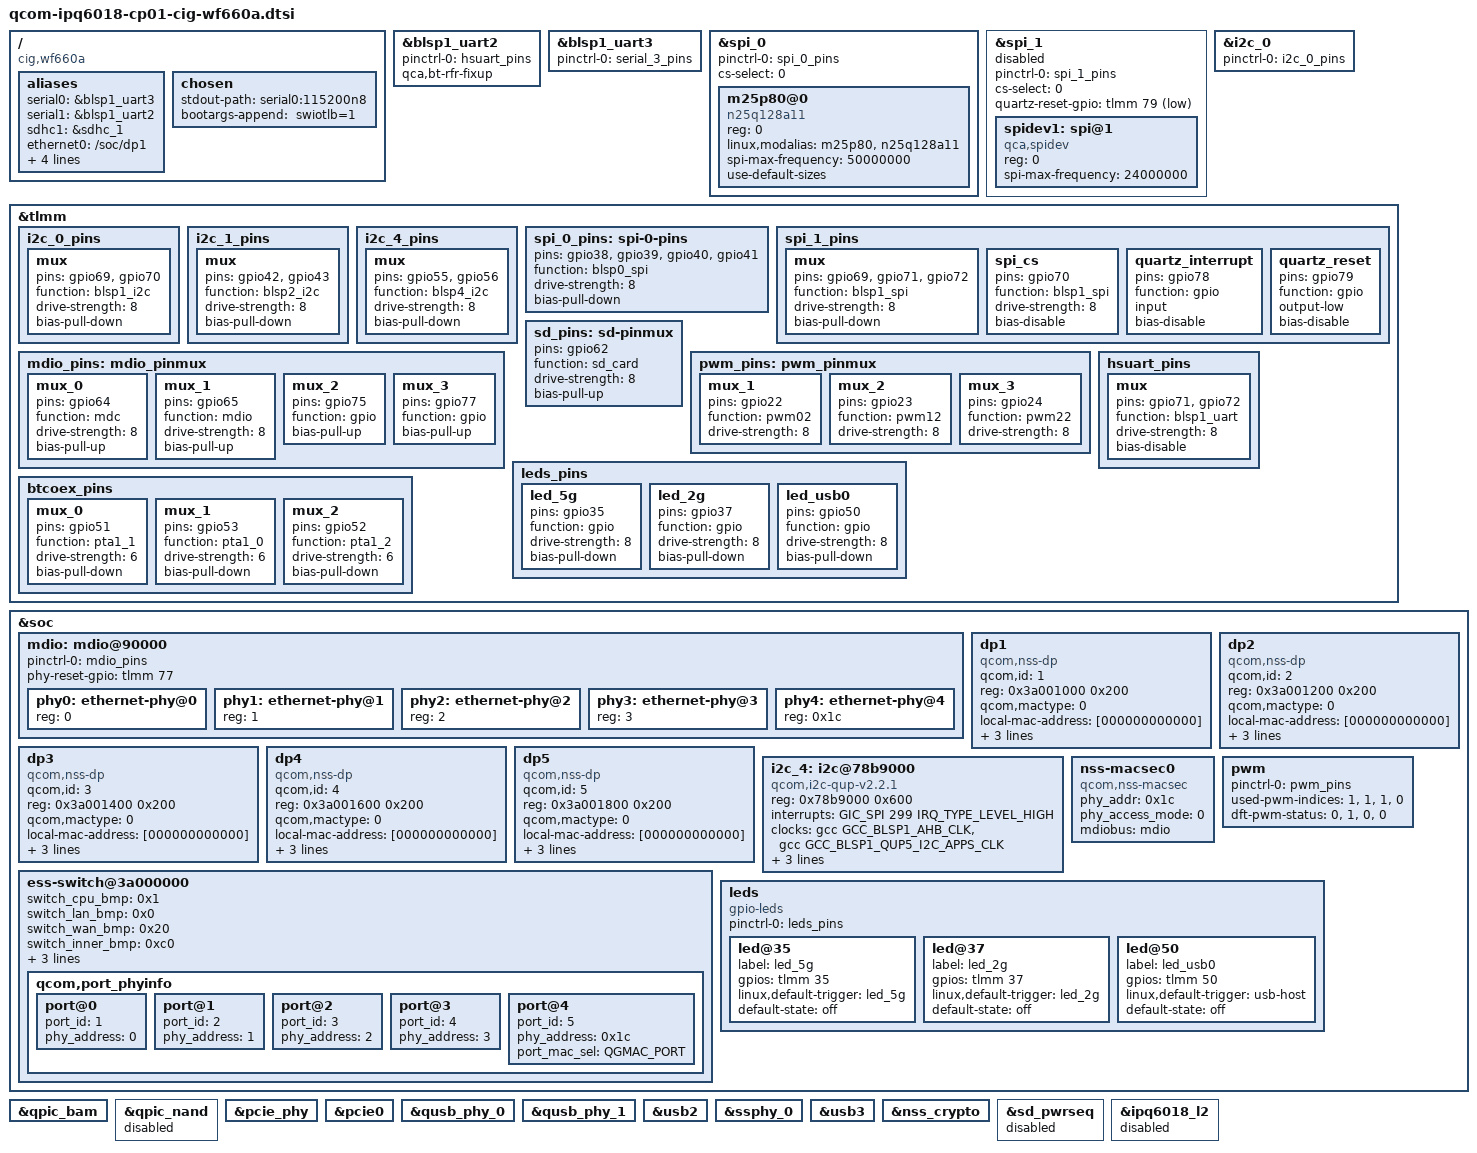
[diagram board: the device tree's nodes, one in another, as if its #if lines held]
// SPDX-License-Identifier: (GPL-2.0+ OR BSD-3-Clause)
/*
 * IPQ6018 CP01 board device tree source
 *
 * Copyright (c) 2019-2021 The Linux Foundation. All rights reserved.
 */

/dts-v1/;

#include "ipq6018.dtsi"
#include "ipq6018-cpr-regulator.dtsi"
#include <dt-bindings/input/input.h>
#include <dt-bindings/gpio/gpio.h>
#include <dt-bindings/pwm/pwm.h>

/ {
    compatible = "cig,wf660a", "qcom,ipq6018-ap-cp01", "qcom,ipq6018";

	aliases {
		serial0 = &blsp1_uart3;
		serial1 = &blsp1_uart2;
		sdhc1 = &sdhc_1;
		/*
		 * Aliases as required by u-boot
		 * to patch MAC addresses
		 */
		ethernet0 = "/soc/dp1";
		ethernet1 = "/soc/dp2";
		ethernet2 = "/soc/dp3";
		ethernet3 = "/soc/dp4";
		ethernet4 = "/soc/dp5";
	};

	chosen {
		stdout-path = "serial0:115200n8";
		bootargs-append = " swiotlb=1";
	};
};

&blsp1_uart2 {
	pinctrl-0 = <&hsuart_pins>;
	pinctrl-names = "default";
	qca,bt-rfr-fixup;
	status = "ok";
};

&blsp1_uart3 {
	pinctrl-0 = <&serial_3_pins>;
	pinctrl-names = "default";
	status = "ok";
};

&spi_0 {
	pinctrl-0 = <&spi_0_pins>;
	pinctrl-names = "default";
	cs-select = <0>;
	status = "ok";

	m25p80@0 {
		#address-cells = <1>;
		#size-cells = <1>;
		reg = <0>;
		compatible = "n25q128a11";
		linux,modalias = "m25p80", "n25q128a11";
		spi-max-frequency = <50000000>;
		use-default-sizes;
	};
};

&spi_1 { /* BLSP1 QUP1 */
	pinctrl-0 = <&spi_1_pins>;
	pinctrl-names = "default";
	cs-select = <0>;
	quartz-reset-gpio = <&tlmm 79 1>;
	status = "disabled";
	spidev1: spi@1 {
		compatible = "qca,spidev";
		reg = <0>;
		spi-max-frequency = <24000000>;
	};
};

&i2c_0 {
	pinctrl-0 = <&i2c_0_pins>;
	pinctrl-names = "default";
	status = "ok";
};

&tlmm {
	i2c_0_pins: i2c_0_pins {
		mux {
			pins = "gpio69", "gpio70";
			function = "blsp1_i2c";
			drive-strength = <8>;
			bias-pull-down;
		};
	};

	i2c_1_pins: i2c_1_pins {
		mux {
			pins = "gpio42", "gpio43";
			function = "blsp2_i2c";
			drive-strength = <8>;
			bias-pull-down;
		};
	};

	i2c_4_pins: i2c_4_pins {
		mux {
			pins = "gpio55", "gpio56";
			function = "blsp4_i2c";
			drive-strength = <8>;
			bias-pull-down;
		};
	};
	
	spi_0_pins: spi-0-pins {
		pins = "gpio38", "gpio39", "gpio40", "gpio41";
		function = "blsp0_spi";
		drive-strength = <8>;
		bias-pull-down;
	};

	spi_1_pins: spi_1_pins {
		mux {
			pins = "gpio69", "gpio71", "gpio72";
			function = "blsp1_spi";
			drive-strength = <8>;
			bias-pull-down;
		};
		spi_cs {
			pins = "gpio70";
			function = "blsp1_spi";
			drive-strength = <8>;
			bias-disable;
		};
		quartz_interrupt {
			pins = "gpio78";
			function = "gpio";
			input;
			bias-disable;
		};
		quartz_reset {
			pins = "gpio79";
			function = "gpio";
			output-low;
			bias-disable;
		};

	};

	sd_pins: sd-pinmux {
		pins = "gpio62";
		function = "sd_card";
		drive-strength = <8>;
		bias-pull-up;
	};

	mdio_pins: mdio_pinmux {
		mux_0 {
			pins = "gpio64";
			function = "mdc";
			drive-strength = <8>;
			bias-pull-up;
		};
		mux_1 {
			pins = "gpio65";
			function = "mdio";
			drive-strength = <8>;
			bias-pull-up;
		};
		mux_2 {
			pins = "gpio75";
			function = "gpio";
			bias-pull-up;
		};
		mux_3 {
			pins = "gpio77";
			function = "gpio";
			bias-pull-up;
		};
	};

	pwm_pins: pwm_pinmux {
		mux_1 {
			pins = "gpio22";
			function = "pwm02";
			drive-strength = <8>;
		};
		mux_2 {
			pins = "gpio23";
			function = "pwm12";
			drive-strength = <8>;
		};
		mux_3 {
			pins = "gpio24";
			function = "pwm22";
			drive-strength = <8>;
		};
	};

	hsuart_pins: hsuart_pins {
		mux {
			pins = "gpio71", "gpio72";
			function = "blsp1_uart";
			drive-strength = <8>;
			bias-disable;
		};
	};

	leds_pins: leds_pins {
		led_5g {
			pins = "gpio35";
			function = "gpio";
			drive-strength = <8>;
			bias-pull-down;
		};
		led_2g {
			pins = "gpio37";
			function = "gpio";
			drive-strength = <8>;
			bias-pull-down;
		};
		led_usb0 {
			pins = "gpio50";
			function = "gpio";
			drive-strength = <8>;
			bias-pull-down;
		};
	};

	btcoex_pins: btcoex_pins {
		mux_0 {
			pins = "gpio51";
			function = "pta1_1";
			drive-strength = <6>;
			bias-pull-down;
		};
		mux_1 {
			pins = "gpio53";
			function = "pta1_0";
			drive-strength = <6>;
			bias-pull-down;
		};
		mux_2 {
			pins = "gpio52";
			function = "pta1_2";
			drive-strength = <6>;
			bias-pull-down;
		};
	};
};

&soc {
	mdio: mdio@90000 {
		pinctrl-0 = <&mdio_pins>;
		pinctrl-names = "default";
		phy-reset-gpio = <&tlmm 77 0>;
		status = "ok";
		phy0: ethernet-phy@0 {
			reg = <0>;
		};
		phy1: ethernet-phy@1 {
			reg = <1>;
		};
		phy2: ethernet-phy@2 {
			reg = <2>;
		};
		phy3: ethernet-phy@3 {
			reg = <3>;
		};
		phy4: ethernet-phy@4 {
			reg = <0x1c>;
		};
	};

	dp1 {
		device_type = "network";
		compatible = "qcom,nss-dp";
		qcom,id = <1>;
		reg = <0x3a001000 0x200>;
		qcom,mactype = <0>;
		local-mac-address = [000000000000];
		qcom,link-poll = <1>;
		qcom,phy-mdio-addr = <0>;
		phy-mode = "sgmii";
	};

	dp2 {
		device_type = "network";
		compatible = "qcom,nss-dp";
		qcom,id = <2>;
		reg = <0x3a001200 0x200>;
		qcom,mactype = <0>;
		local-mac-address = [000000000000];
		qcom,link-poll = <1>;
		qcom,phy-mdio-addr = <1>;
		phy-mode = "sgmii";
	};

	dp3 {
		device_type = "network";
		compatible = "qcom,nss-dp";
		qcom,id = <3>;
		reg = <0x3a001400 0x200>;
		qcom,mactype = <0>;
		local-mac-address = [000000000000];
		qcom,link-poll = <1>;
		qcom,phy-mdio-addr = <2>;
		phy-mode = "sgmii";
	};

	dp4 {
		device_type = "network";
		compatible = "qcom,nss-dp";
		qcom,id = <4>;
		reg = <0x3a001600 0x200>;
		qcom,mactype = <0>;
		local-mac-address = [000000000000];
		qcom,link-poll = <1>;
		qcom,phy-mdio-addr = <3>;
		phy-mode = "sgmii";
	};

	dp5 {
		device_type = "network";
		compatible = "qcom,nss-dp";
		qcom,id = <5>;
		reg = <0x3a001800 0x200>;
		qcom,mactype = <0>;
		local-mac-address = [000000000000];
		qcom,link-poll = <1>;
		qcom,phy-mdio-addr = <28>;
		phy-mode = "sgmii";
	};

	i2c_4: i2c@78b9000 {
		compatible = "qcom,i2c-qup-v2.2.1";
		#address-cells = <1>;
		#size-cells = <0>;
		reg = <0x78b9000 0x600>;
		interrupts = <GIC_SPI 299 IRQ_TYPE_LEVEL_HIGH>;
		clocks = <&gcc GCC_BLSP1_AHB_CLK>,
				<&gcc GCC_BLSP1_QUP5_I2C_APPS_CLK>;
		clock-names = "iface", "core";
		clock-frequency  = <100000>;
		dmas = <&blsp_dma 21>, <&blsp_dma 20>;
		dma-names = "rx", "tx";
		pinctrl-0 = <&i2c_4_pins>;
		status = "ok";
	};

	ess-switch@3a000000 {
		switch_cpu_bmp = <0x1>;  /* cpu port bitmap */
		switch_lan_bmp = <0x0>; /* lan port bitmap */
		switch_wan_bmp = <0x20>; /* wan port bitmap */
		switch_inner_bmp = <0xc0>; /*inner port bitmap*/
		switch_mac_mode = <0x0>; /* mac mode for uniphy instance0*/
		switch_mac_mode1 = <0xf>; /* mac mode for uniphy instance1*/
		switch_mac_mode2 = <0xff>; /* mac mode for uniphy instance2*/
		qcom,port_phyinfo {
			port@0 {
				port_id = <1>;
				phy_address = <0>;
			};
			port@1 {
				port_id = <2>;
				phy_address = <1>;
			};
			port@2 {
				port_id = <3>;
				phy_address = <2>;
			};
			port@3 {
				port_id = <4>;
				phy_address = <3>;
			};
			port@4 {
				port_id = <5>;
				phy_address = <0x1c>;
				port_mac_sel = "QGMAC_PORT";
			};
		};
	};

	nss-macsec0 {
		compatible = "qcom,nss-macsec";
		phy_addr = <0x1c>;
		phy_access_mode = <0>;
		mdiobus = <&mdio>;
	};

	pwm {
		pinctrl-0 = <&pwm_pins>;
		pinctrl-names = "default";
		used-pwm-indices = <1>, <1>, <1>, <0>;
		dft-pwm-status = <0>, <1>, <0>, <0>;
		status = "ok";
	};

	leds {
		compatible = "gpio-leds";
		pinctrl-0 = <&leds_pins>;
		pinctrl-names = "default";

		led@35 {
			label = "led_5g";
			gpios = <&tlmm 35 GPIO_ACTIVE_HIGH>;
			linux,default-trigger = "led_5g";
			default-state = "off";
		};
		led@37 {
			label = "led_2g";
			gpios = <&tlmm 37 GPIO_ACTIVE_HIGH>;
			linux,default-trigger = "led_2g";
			default-state = "off";
		};
		led@50 {
			label = "led_usb0";
			gpios = <&tlmm 50 GPIO_ACTIVE_HIGH>;
			linux,default-trigger = "usb-host";
			default-state = "off";
		};
	};
};

&qpic_bam {
	status = "ok";
};

&qpic_nand {
	status = "disable";
};

&pcie_phy {
	status = "ok";
};

&pcie0 {
#if defined(__CNSS2__)
	status = "ok";
#endif
};

&qusb_phy_0 {
	status = "ok";
};

&qusb_phy_1 {
	status = "ok";
};

&usb2 {
	status = "ok";
};

&ssphy_0 {
	status = "ok";
};

&usb3 {
	status = "ok";
};

&nss_crypto {
	status = "ok";
};

&sd_pwrseq {
	status = "disable";
};

&ipq6018_l2 {
	status = "disable";
};
